# APM32F446 register map
File version: 1.0
CPU: CM4 r0p1, little endian, MPU, FPU, 4 interrupt priority bits
Registers are 32-bit, read-write, reset 0x0 unless marked. A register's access mark holds for its fields unless they carry their own. Offsets are from the block's base; [hi:lo] are bit positions; {n}, {i} and the like mark numbered series; 'fields as' and 'values as' point back to an identical list.

## MPU — Memory Protection Unit
Base 0x4000D000
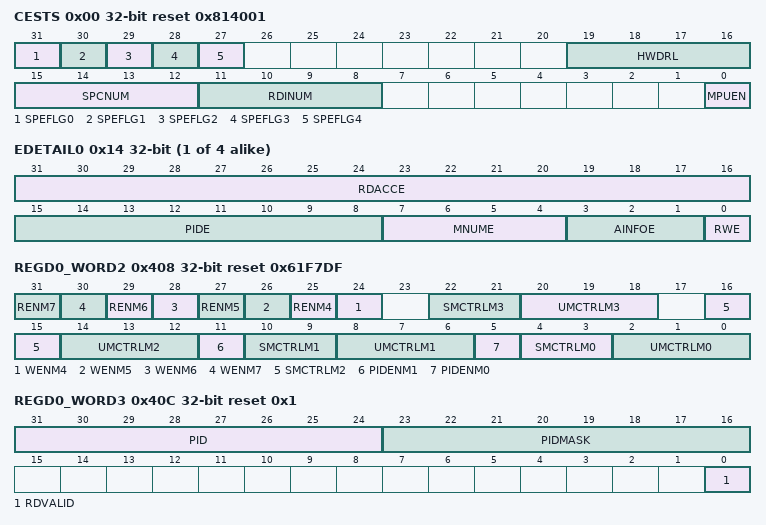
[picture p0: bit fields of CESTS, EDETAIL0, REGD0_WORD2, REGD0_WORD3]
0x00 CESTS reset 0x814001 — Control/Error Status Register
  [31] SPEFLG0 — Slave Port 2 Error Occurred Flag
    0=No error has occurred for slave port 0; 1=An error has occurred for slave port 0
  [30] SPEFLG1 — Slave Port 2 Error Occurred Flag
    0=No error has occurred for slave port 1; 1=An error has occurred for slave port 1
  [29] SPEFLG2 — Slave Port 2 Error Occurred Flag
    0=No error has occurred for slave port 2; 1=An error has occurred for slave port 2
  [28] SPEFLG3 — Slave Port 3 Error Occurred Flag
    0=No error has occurred for slave port 3; 1=An error has occurred for slave port 3
  [27] SPEFLG4 — Slave Port 4 Error Occurred Flag
    values as SPEFLG3
  [19:16] HWDRL ro — Hardware and Definition Revision Level
  [15:12] SPCNUM ro — Slave Ports Connected Number
  [11:8] RDINUM ro — Region Descriptors Number
    0=8 region descriptors; 1=12 region descriptors; 2=16 region descriptors
  [0] MPUEN — MPU Global Enable
    0=MPU is disabled. All accesses from all bus masters are allowed.; 1=MPU is enabled
0x10 EADDR0 ro — Error Address Register, slave port 0
  [31:0] SACCEADDR — Error Address
{0x14+8i} EDETAIL{i} ro (i=0..3) — Error Detail Register, slave port {i}
  [31:16] RDACCE — Region Descriptor with the Access Error
  [15:8] PIDE — Process Identification of Error
  [7:4] MNUME — Master Number of Error
  [3:1] AINFOE — Attribute Information of Error
    0=User mode, instruction access; 1=User mode, data access; 2=Supervisor mode, instruction access; 3=Supervisor mode, data access
  [0] RWE — Read/Write Error
    0=Read; 1=Write
0x18 EADDR1 ro — Error Address Register, slave port
  [31:0] SACCEADDR — Error Address
0x20 EADDR2 ro — Error Address Register, slave port 2
  [31:0] SACCEADDR — Error Address
0x28 EADDR3 ro — Error Address Register, slave port 3
  [31:0] SACCEADDR — Error Address
{0x400+0x10*i} REGD{i}_WORD0 (i=0..7) — Region Descriptor {i}, Word Register 0
  [31:5] SADDR — Start Address of the Memory Region
0x404 REGD0_WORD1 reset 0xFFFFFFFF — Region Descriptor 0, Word Register 1
  [31:5] ENDADDR — End Address of the Memory Region
0x408 REGD0_WORD2 reset 0x61F7DF — Region Descriptor 0, Word Register 2
  [2n+17] RENM{n} (n=4..7) — Bus Master {n} Read Enable
    0=Bus master {n} reads terminate with an access error and the read is not performed; 1=Bus master {n} reads allowed
  [2n+16] WENM{n} (n=4..7) — Bus Master {n} Write Enable
    0=Bus master {n} writes terminate with an access error and the write is not performed; 1=Bus master {n} writes allowed
  [6n+4:6n+3] SMCTRLM{n} (n=0..3) — Bus Master {n} Supervisor Mode Access Control
    0=r/w/x; read, write and execute allowed; 1=r/x; read and execute allowed, but no write; 2=r/w; read and write allowed, but no execute; 3=Same as User mode defined in UMCTRLM{n}
  [20:18] UMCTRLM3 — Bus Master 3 User Mode Access Control
  [14:12] UMCTRLM2 — Bus Master 2 User Mode Access control
  [11] PIDENM1 — Bus Master 1 Process Identifier enable
    0=Do not include the process identifier in the evaluation; 1=Include the process identifier and mask (RGDn.RGDAACC) in the region hit evaluation
  [8:6] UMCTRLM1 — Bus Master 1 User Mode Access Control
  [5] PIDENM0 — Bus Master 0 Process Identifier enable
    values as PIDENM1
  [2:0] UMCTRLM0 — Bus Master 0 User Mode Access Control
0x40C REGD0_WORD3 reset 0x1 — Region Descriptor 0, Word Register 3
  [31:24] PID — Process Identifier
  [23:16] PIDMASK — Process Identifier Mask
  [0] RDVALID — Region Descriptor Valid
    0=Region descriptor is invalid; 1=Region descriptor is valid
{0x404+0x10*i} REGD{i}_WORD1 reset 0x1F (i=1..7) — Region Descriptor {i}, Word Register 1
  [31:5] ENDADDR — End Address of the Memory Region
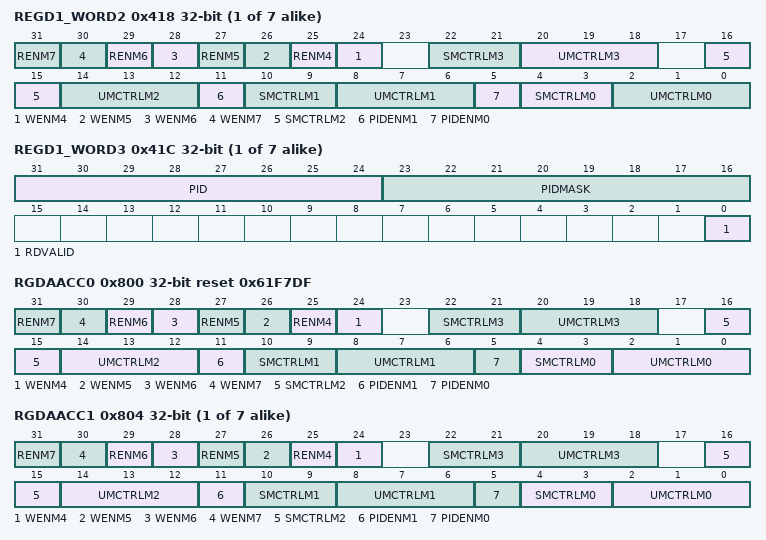
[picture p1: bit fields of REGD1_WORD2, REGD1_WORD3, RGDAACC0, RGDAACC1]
{0x408+0x10*i} REGD{i}_WORD2 (i=1..7) — Region Descriptor {i}, Word Register 2
  fields as REGD0_WORD2
{0x40C+0x10*i} REGD{i}_WORD3 (i=1..7) — Region Descriptor {i}, Word Register 3
  fields as REGD0_WORD3
0x800 RGDAACC0 reset 0x61F7DF — Region Descriptor Alternate Access Control 0
  [2n+17] RENM{n} (n=4..7) — Bus Master {n} Read Enable
    values as REGD0_WORD2.RENM4
  [2n+16] WENM{n} (n=4..7) — Bus Master {n} Write Enable
    values as REGD0_WORD2.WENM4
  [6n+4:6n+3] SMCTRLM{n} (n=0..3) — Bus Master {n} Supervisor Mode Access Control
    values as REGD0_WORD2.SMCTRLM0
  [6n+2:6n] UMCTRLM{n} (n=0..3) — Bus Master {n} User Mode Access Control
  [11] PIDENM1 — Bus Master 1 Process Identifier Enable
    values as REGD0_WORD2.PIDENM1
  [5] PIDENM0 — Bus Master 0 Process Identifier Enable
    values as REGD0_WORD2.PIDENM1
{0x800+4i} RGDAACC{i} (i=1..7) — Region Descriptor Alternate Access Control {i}
  fields as RGDAACC0
